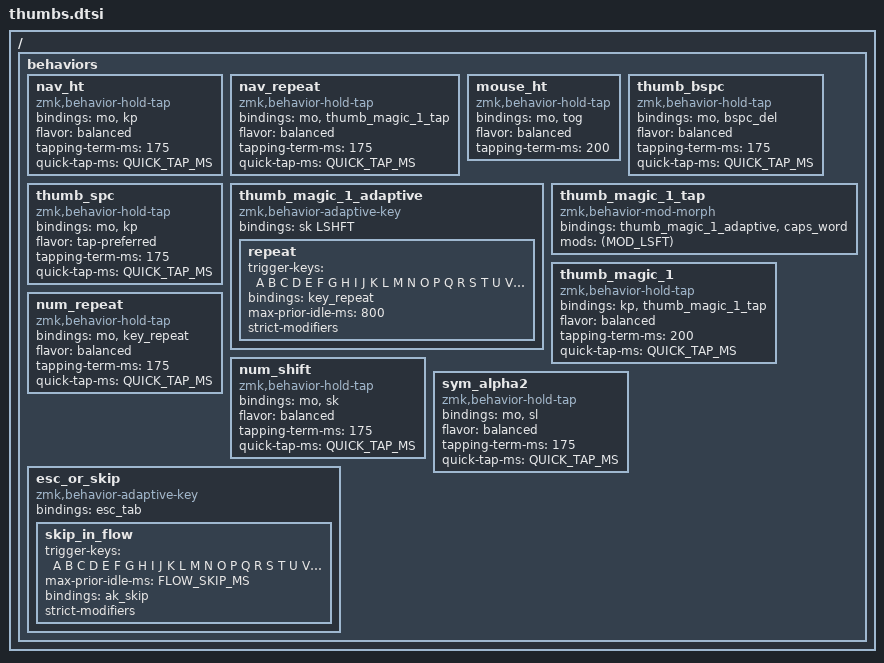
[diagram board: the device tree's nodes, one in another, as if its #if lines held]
ZMK_HOLD_TAP(nav_ht, bindings = <&mo>, <&kp>;
             flavor = "balanced"; tapping-term-ms = <175>;
             quick-tap-ms = <QUICK_TAP_MS>;)

ZMK_HOLD_TAP(nav_repeat, bindings = <&mo>, <&thumb_magic_1_tap>;
             flavor = "balanced"; tapping-term-ms = <175>;
             quick-tap-ms = <QUICK_TAP_MS>;)

ZMK_HOLD_TAP(mouse_ht, bindings = <&mo>, <&tog>;
             flavor = "balanced"; tapping-term-ms = <200>;)

ZMK_HOLD_TAP(thumb_bspc, bindings = <&mo>, <&bspc_del>;
             flavor = "balanced"; tapping-term-ms = <175>;
             quick-tap-ms = <QUICK_TAP_MS>;)

ZMK_HOLD_TAP(thumb_spc, bindings = <&mo>, <&kp>;
             flavor = "tap-preferred"; tapping-term-ms = <175>;
             quick-tap-ms = <QUICK_TAP_MS>;)

ZMK_ADAPTIVE_KEY(thumb_magic_1_adaptive, bindings = <&sk LSHFT>;
    repeat {
      trigger-keys = <A B C D E F G H I J K L M N O P Q R S T U V W X Y Z>;
      bindings = <&key_repeat>;
      max-prior-idle-ms = <800>;
      strict-modifiers;
    };
)

ZMK_MOD_MORPH(thumb_magic_1_tap, bindings = <&thumb_magic_1_adaptive>, <&caps_word>;
              mods = <(MOD_LSFT)>;)

ZMK_HOLD_TAP(thumb_magic_1, bindings = <&kp>, <&thumb_magic_1_tap>;
             flavor = "balanced"; tapping-term-ms = <200>;
             quick-tap-ms = <QUICK_TAP_MS>;)

ZMK_HOLD_TAP(num_repeat, bindings = <&mo>, <&key_repeat>;
             flavor = "balanced"; tapping-term-ms = <175>;
             quick-tap-ms = <QUICK_TAP_MS>;)

ZMK_HOLD_TAP(num_shift, bindings = <&mo>, <&sk>;
             flavor = "balanced"; tapping-term-ms = <175>;
             quick-tap-ms = <QUICK_TAP_MS>;)

ZMK_HOLD_TAP(sym_alpha2, bindings = <&mo>, <&sl>;
             flavor = "balanced"; tapping-term-ms = <175>;
             quick-tap-ms = <QUICK_TAP_MS>;)

#define THUMB_MAGIC &thumb_magic_1 LSHFT 0

#define ALPHA_THUMBS_L &thumb_spc LAYER_Nav SPACE &nav_ht LAYER_Symbol ESC
#define VESTNIK_THUMBS_L &thumb_spc LAYER_Nav SPACE &sym_alpha2 LAYER_Symbol LAYER_VestnikX
#define ALPHA_THUMBS_R &lt LAYER_Num RET THUMB_MAGIC

#ifndef FLOW_SKIP_MS
#define FLOW_SKIP_MS 400
#endif

#ifdef ENABLE_ESC_OR_SKIP
ZMK_ADAPTIVE_KEY(esc_or_skip, bindings = <&esc_tab>;
    skip_in_flow {
      trigger-keys = <A B C D E F G H I J K L M N O P Q R S T U V W X Y Z>;
      max-prior-idle-ms = <FLOW_SKIP_MS>;
      bindings = <&ak_skip>;
      strict-modifiers;
    };
)
#endif
